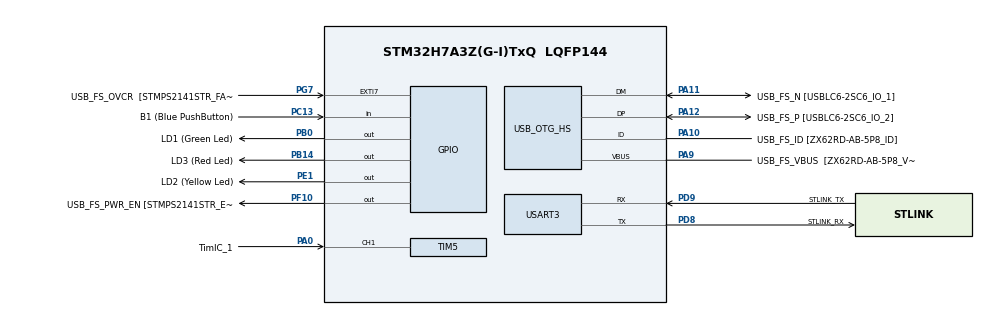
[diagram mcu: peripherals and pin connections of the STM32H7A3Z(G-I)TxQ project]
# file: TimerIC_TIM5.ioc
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Mcu.Family=STM32H7
Mcu.Name=STM32H7A3Z(G-I)TxQ
Mcu.Package=LQFP144
NVIC.PriorityGroup=NVIC_PRIORITYGROUP_4
NVIC.TIM5_IRQn=true\:0\:0\:false\:false\:true\:true\:true\:true
PA0.GPIO_Label=TimIC_1
PA0.GPIO_PuPd=GPIO_PULLDOWN
PA0.GPIO_Speed=GPIO_SPEED_FREQ_VERY_HIGH
PA0.Signal=S_TIM5_CH1
PA10.GPIO_Label=USB_FS_ID [ZX62RD-AB-5P8_ID]
PA10.Mode=OTG/Dual-Role-Device-FS
PA10.Signal=USB_OTG_HS_ID
PA11.GPIO_Label=USB_FS_N [USBLC6-2SC6_IO_1]
PA11.Mode=OTG/Dual-Role-Device-FS
PA11.Signal=USB_OTG_HS_DM
PA12.GPIO_Label=USB_FS_P [USBLC6-2SC6_IO_2]
PA12.Mode=OTG/Dual-Role-Device-FS
PA12.Signal=USB_OTG_HS_DP
PA9.GPIO_Label=USB_FS_VBUS  [ZX62RD-AB-5P8_VBUS]
PA9.Mode=Activate_VBUS_FS
PA9.Signal=USB_OTG_HS_VBUS
PB0.GPIO_Label=LD1 (Green Led)
PB0.Signal=GPIO_Output
PB14.GPIO_Label=LD3 (Red Led)
PB14.Signal=GPIO_Output
PC13.GPIO_Label=B1 (Blue PushButton)
PC13.Signal=GPIO_Input
PC14-OSC32_IN.GPIO_Label=OSC32_IN
PC14-OSC32_IN.Mode=LSE-External-Oscillator
PC14-OSC32_IN.Signal=RCC_OSC32_IN
PC15-OSC32_OUT.GPIO_Label=OSC32_OUT
PC15-OSC32_OUT.Mode=LSE-External-Oscillator
PC15-OSC32_OUT.Signal=RCC_OSC32_OUT
PD8.GPIO_Label=STLINK_RX
PD8.Mode=Asynchronous
PD8.Signal=USART3_TX
PD9.GPIO_Label=STLINK_TX
PD9.Mode=Asynchronous
PD9.Signal=USART3_RX
PE1.GPIO_Label=LD2 (Yellow Led)
PE1.Signal=GPIO_Output
PF10.GPIO_Label=USB_FS_PWR_EN [STMPS2141STR_EN]
PF10.Signal=GPIO_Output
PG7.GPIO_Label=USB_FS_OVCR  [STMPS2141STR_FAULT]
PG7.Signal=GPXTI7
PH0-OSC_IN.GPIO_Label=PH0-MCU
PH0-OSC_IN.Mode=HSE-External-Clock-Source
PH0-OSC_IN.Signal=RCC_OSC_IN
PH1-OSC_OUT.GPIO_Label=PH1-MCU
PH1-OSC_OUT.Signal=RCC_OSC_OUT
ProjectManager.HeapSize=0x200
ProjectManager.StackSize=0x400
ProjectManager.TargetToolchain=MDK-ARM V5.32
RCC.ADCFreq_Value=16125000
RCC.APB1Freq_Value=100000000
RCC.APB2Freq_Value=100000000
RCC.APB3Freq_Value=100000000
RCC.APB4Freq_Value=100000000
RCC.CDPPRE=RCC_APB3_DIV2
RCC.CDPPRE1=RCC_APB1_DIV2
RCC.CDPPRE2=RCC_APB2_DIV2
RCC.CortexFreq_Value=200000000
RCC.DIVM1=1
RCC.DIVM3=1
RCC.DIVN1=50
RCC.DIVN3=24
RCC.DIVQ1=4
RCC.HCLKFreq_Value=200000000
RCC.HSE_VALUE=8000000
RCC.PLLFRACN=0
RCC.PLLSourceVirtual=RCC_PLLSOURCE_HSE
RCC.PWR_Regulator_Voltage_Scale=PWR_REGULATOR_VOLTAGE_SCALE0
RCC.SRDPPRE=RCC_APB4_DIV2
RCC.SYSCLKFreq_VALUE=200000000
RCC.SYSCLKSource=RCC_SYSCLKSOURCE_PLLCLK
RCC.SupplySource=PWR_DIRECT_SMPS_SUPPLY
RCC.USBCLockSelection=RCC_USBCLKSOURCE_HSI48
RCC.USBFreq_Value=48000000
SH.S_TIM5_CH1.0=TIM5_CH1,Input_Capture1_from_TI1
TIM5.Channel-Input_Capture1_from_TI1=TIM_CHANNEL_1
TIM5.Prescaler=200-1
USART3.VirtualMode-Asynchronous=VM_ASYNC
VP_TIM5_VS_ClockSourceINT.Mode=Internal
board=NUCLEO-H7A3ZI-Q

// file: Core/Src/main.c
/* USER CODE BEGIN Header */
/**
  ******************************************************************************
  * @file           : main.c
  * @brief          : Main program body
  ******************************************************************************
  * @attention
  *
  * Copyright (c) 2024 STMicroelectronics.
  * All rights reserved.
  *
  * This software is licensed under terms that can be found in the LICENSE file
  * in the root directory of this software component.
  * If no LICENSE file comes with this software, it is provided AS-IS.
  *
  ******************************************************************************
  */
/* USER CODE END Header */
#include "main.h"
#include "tim.h"
#include "usart.h"
#include "usb_otg.h"
#include "gpio.h"
#include "stdio.h"
#include "bsp_timer_ic.h"

void SystemClock_Config(void);

int main(void)
{

  /* MCU Configuration--------------------------------------------------------*/

  /* Reset of all peripherals, Initializes the Flash interface and the Systick. */
  HAL_Init();

  /* Configure the system clock */
  SystemClock_Config();

  /* Initialize all configured peripherals */
  MX_GPIO_Init();
  MX_TIM5_Init();
  MX_USART3_UART_Init();
  MX_USB_OTG_HS_USB_Init();
  /* USER CODE BEGIN 2 */
	printf("System ON \r\n");
  /* USER CODE END 2 */

  /* Infinite loop */
  while (1)
  {
		bsp_TIM5_CH1_Capture_Hight_Time();
  }
}

void SystemClock_Config(void)
{
  RCC_OscInitTypeDef RCC_OscInitStruct = {0};
  RCC_ClkInitTypeDef RCC_ClkInitStruct = {0};

  /*AXI clock gating */
  RCC->CKGAENR = 0xFFFFFFFF;

  /** Supply configuration update enable
  */
  HAL_PWREx_ConfigSupply(PWR_DIRECT_SMPS_SUPPLY);

  /** Configure the main internal regulator output voltage
  */
  __HAL_PWR_VOLTAGESCALING_CONFIG(PWR_REGULATOR_VOLTAGE_SCALE0);

  while(!__HAL_PWR_GET_FLAG(PWR_FLAG_VOSRDY)) {}

  /** Initializes the RCC Oscillators according to the specified parameters
  * in the RCC_OscInitTypeDef structure.
  */
  RCC_OscInitStruct.OscillatorType = RCC_OSCILLATORTYPE_HSI48|RCC_OSCILLATORTYPE_HSE;
  RCC_OscInitStruct.HSEState = RCC_HSE_BYPASS;
  RCC_OscInitStruct.HSI48State = RCC_HSI48_ON;
  RCC_OscInitStruct.PLL.PLLState = RCC_PLL_ON;
  RCC_OscInitStruct.PLL.PLLSource = RCC_PLLSOURCE_HSE;
  RCC_OscInitStruct.PLL.PLLM = 1;
  RCC_OscInitStruct.PLL.PLLN = 50;
  RCC_OscInitStruct.PLL.PLLP = 2;
  RCC_OscInitStruct.PLL.PLLQ = 4;
  RCC_OscInitStruct.PLL.PLLR = 2;
  RCC_OscInitStruct.PLL.PLLRGE = RCC_PLL1VCIRANGE_3;
  RCC_OscInitStruct.PLL.PLLVCOSEL = RCC_PLL1VCOWIDE;
  RCC_OscInitStruct.PLL.PLLFRACN = 0;
  if (HAL_RCC_OscConfig(&RCC_OscInitStruct) != HAL_OK)
  {
    Error_Handler();
  }

  /** Initializes the CPU, AHB and APB buses clocks
  */
  RCC_ClkInitStruct.ClockType = RCC_CLOCKTYPE_HCLK|RCC_CLOCKTYPE_SYSCLK
                              |RCC_CLOCKTYPE_PCLK1|RCC_CLOCKTYPE_PCLK2
                              |RCC_CLOCKTYPE_D3PCLK1|RCC_CLOCKTYPE_D1PCLK1;
  RCC_ClkInitStruct.SYSCLKSource = RCC_SYSCLKSOURCE_PLLCLK;
  RCC_ClkInitStruct.SYSCLKDivider = RCC_SYSCLK_DIV1;
  RCC_ClkInitStruct.AHBCLKDivider = RCC_HCLK_DIV1;
  RCC_ClkInitStruct.APB3CLKDivider = RCC_APB3_DIV2;
  RCC_ClkInitStruct.APB1CLKDivider = RCC_APB1_DIV2;
  RCC_ClkInitStruct.APB2CLKDivider = RCC_APB2_DIV2;
  RCC_ClkInitStruct.APB4CLKDivider = RCC_APB4_DIV2;

  if (HAL_RCC_ClockConfig(&RCC_ClkInitStruct, FLASH_LATENCY_4) != HAL_OK)
  {
    Error_Handler();
  }
}

void Error_Handler(void)
{
  __disable_irq();
  while (1)
  {
  }
}
